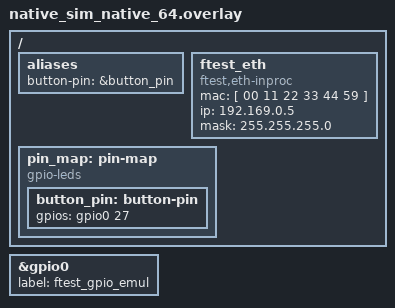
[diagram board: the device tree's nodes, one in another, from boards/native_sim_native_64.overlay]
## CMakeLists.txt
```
# SPDX-License-Identifier: Apache-2.0

cmake_minimum_required(VERSION 3.20.0)

list(APPEND ZEPHYR_EXTRA_MODULES ${CMAKE_CURRENT_SOURCE_DIR}/../_modules/entity_lib)

find_package(Zephyr REQUIRED HINTS $ENV{ZEPHYR_BASE})
project(button)

target_sources(app PRIVATE src/main.c)
```

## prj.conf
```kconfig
CONFIG_NO_OPTIMIZATIONS=y
```

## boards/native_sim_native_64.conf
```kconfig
CONFIG_NATIVE_SIM_SLOWDOWN_TO_REAL_TIME=n
CONFIG_POSIX_API=y

CONFIG_GPIO=y
CONFIG_GPIO_EMUL=y

CONFIG_NET_L2_ETHERNET=y
CONFIG_ETH_NATIVE_TAP=n
CONFIG_NET_SOCKETS=y
CONFIG_NETWORKING=y
CONFIG_NET_IPV4=y
CONFIG_NET_TCP=y
CONFIG_NET_ARP=y

CONFIG_LOG=y
CONFIG_LOG_MAX_LEVEL=4
```

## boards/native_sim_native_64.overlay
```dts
/ {
    aliases {
        button-pin  = &button_pin;
    };

    ftest_eth: ftest_eth {
        compatible = "ftest,eth-inproc";
        mac = [ 00 11 22 33 44 59  ];
        ip = "192.169.0.5";
        mask = "255.255.255.0";
    };

    pin_map: pin-map {
        compatible = "gpio-leds";
        button_pin: button-pin {
            gpios = <&gpio0 27 GPIO_ACTIVE_HIGH>;
        };
    };
};

&gpio0 {
    status = "okay";
    label = "ftest_gpio_emul";
};
```

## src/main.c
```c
#include <zephyr/kernel.h>
#include <stdio.h>

int main(void)
{
	k_sleep(K_SECONDS(5));

	printf("Hello, Zephyr!\n");

	return 0;
}
```
